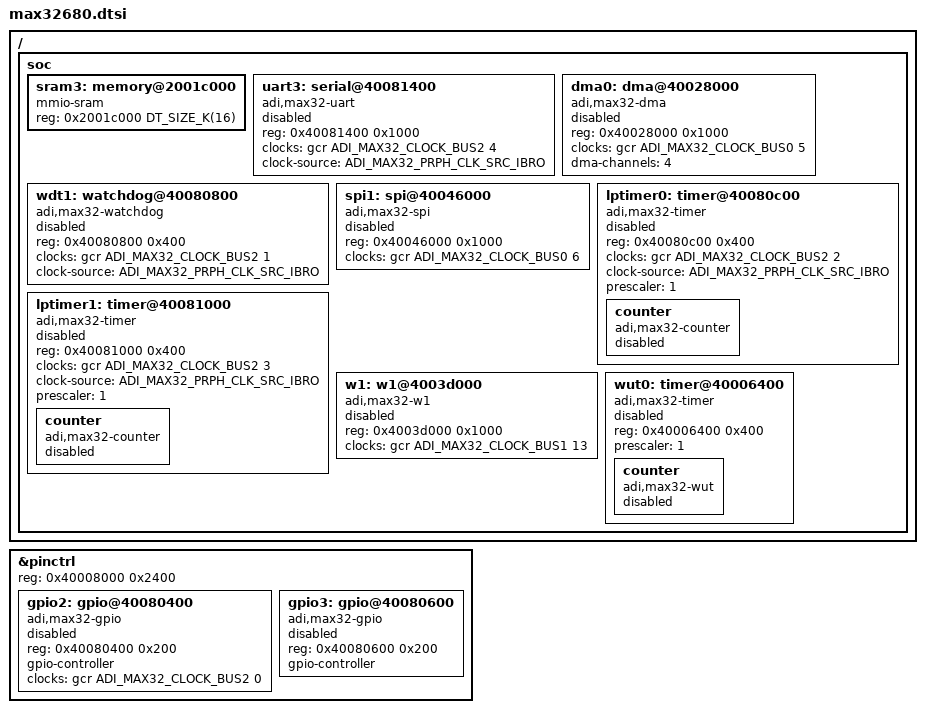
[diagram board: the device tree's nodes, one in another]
/*
 * Copyright (c) 2024-2025 Analog Devices, Inc.
 *
 * SPDX-License-Identifier: Apache-2.0
 */

#include <adi/max32/max32xxx.dtsi>
#include <zephyr/dt-bindings/dma/max32680_dma.h>

&pinctrl {
	reg = <0x40008000 0x2400>;

	gpio2: gpio@40080400 {
		reg = <0x40080400 0x200>;
		compatible = "adi,max32-gpio";
		gpio-controller;
		#gpio-cells = <2>;
		clocks = <&gcr ADI_MAX32_CLOCK_BUS2 0>;
		status = "disabled";
	};

	gpio3: gpio@40080600 {
		reg = <0x40080600 0x200>;
		compatible = "adi,max32-gpio";
		gpio-controller;
		#gpio-cells = <2>;
		status = "disabled";
	};
};

/ {
	soc {
		sram3: memory@2001c000 {
			compatible = "mmio-sram";
			reg = <0x2001c000 DT_SIZE_K(16)>;
		};

		uart3: serial@40081400 {
			compatible = "adi,max32-uart";
			reg = <0x40081400 0x1000>;
			clocks = <&gcr ADI_MAX32_CLOCK_BUS2 4>;
			clock-source = <ADI_MAX32_PRPH_CLK_SRC_IBRO>;
			status = "disabled";
		};

		dma0: dma@40028000 {
			compatible = "adi,max32-dma";
			reg = <0x40028000 0x1000>;
			clocks = <&gcr ADI_MAX32_CLOCK_BUS0 5>;
			dma-channels = <4>;
			status = "disabled";
			#dma-cells = <2>;
		};

		wdt1: watchdog@40080800 {
			compatible = "adi,max32-watchdog";
			reg = <0x40080800 0x400>;
			clocks = <&gcr ADI_MAX32_CLOCK_BUS2 1>;
			clock-source = <ADI_MAX32_PRPH_CLK_SRC_IBRO>;
			status = "disabled";
		};

		spi1: spi@40046000 {
			compatible = "adi,max32-spi";
			reg = <0x40046000 0x1000>;
			#address-cells = <1>;
			#size-cells = <0>;
			clocks = <&gcr ADI_MAX32_CLOCK_BUS0 6>;
			status = "disabled";
		};

		lptimer0: timer@40080c00 {
			compatible = "adi,max32-timer";
			reg = <0x40080c00 0x400>;
			status = "disabled";
			clocks = <&gcr ADI_MAX32_CLOCK_BUS2 2>;
			clock-source = <ADI_MAX32_PRPH_CLK_SRC_IBRO>;
			prescaler = <1>;

			counter {
				compatible = "adi,max32-counter";
				status = "disabled";
			};
		};

		lptimer1: timer@40081000 {
			compatible = "adi,max32-timer";
			reg = <0x40081000 0x400>;
			status = "disabled";
			clocks = <&gcr ADI_MAX32_CLOCK_BUS2 3>;
			clock-source = <ADI_MAX32_PRPH_CLK_SRC_IBRO>;
			prescaler = <1>;

			counter {
				compatible = "adi,max32-counter";
				status = "disabled";
			};
		};

		w1: w1@4003d000 {
			compatible = "adi,max32-w1";
			reg = <0x4003d000 0x1000>;
			clocks = <&gcr ADI_MAX32_CLOCK_BUS1 13>;
			status = "disabled";
		};

		wut0: timer@40006400 {
			compatible = "adi,max32-timer";
			reg = <0x40006400 0x400>;
			status = "disabled";
			prescaler = <1>;

			counter {
				compatible = "adi,max32-wut";
				status = "disabled";
			};
		};
	};
};
